AUTOSAR XML (schema 4-0-3)
package /ComponentTypes
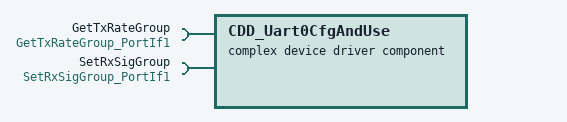
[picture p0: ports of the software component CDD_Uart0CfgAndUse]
  complex device driver sw component type CDD_Uart0CfgAndUse
    require port GetTxRateGroup: client-com-spec=Oper, required-interface=GetTxRateGroup_PortIf1
    require port SetRxSigGroup: client-com-spec=Oper, required-interface=SetRxSigGroup_PortIf1
    behavior CDD_Uart0CfgAndUse_InternalBehavior
      exclusive area ExclsvAr1Uart0DrvrTxRxBuf
      ar-typed-per-instance-memorys:
        13 x data, all with sw-calibration-access=READ-ONLY:
          PrevDmaTrfCnt: type=uint16
          Uart0100MilliSecBufCnt: type=Ary1D_u8_2048_Uart0CfgAndUse
          Uart0100MilliSecReadCmpl: type=uint8
          Uart010MilliSecBufCnt: type=Ary1D_u8_2048_Uart0CfgAndUse
          Uart010MilliSecReadCmpl: type=uint8
          Uart02MilliSecBufCnt: type=Ary1D_u8_2048_Uart0CfgAndUse
          Uart0DiagcFrmErrCntr: type=uint32
          Uart0DiagcOvrrunErrCntr: type=uint32
          Uart0DiagcParErrCntr: type=uint32
          Uart0DiagcRxMaxDataErrCntr: type=uint32
          Uart0NrOfPnd100MilliSecFrmCnt: type=uint8
          Uart0NrOfPnd10MilliSecFrmCnt: type=uint8
          Uart0RxPrevLoopDataUnread: type=uint8
      5 x timing event:
        CDD_Uart0CfgAndUse_InitEvent: start-on-event=Uart0CfgAndUseInit1, period=0
        TMT_Uart0CfgAndUsePer1: start-on-event=Uart0CfgAndUsePer1, period=0.002
        TMT_Uart0CfgAndUsePer2: start-on-event=Uart0CfgAndUsePer2, period=0.002
        TMT_Uart0CfgAndUsePer3: start-on-event=Uart0CfgAndUsePer3, period=0.01
        TMT_Uart0CfgAndUsePer4: start-on-event=Uart0CfgAndUsePer4, period=0.1
      5 x runnable:
        Uart0CfgAndUseInit1
        Uart0CfgAndUsePer1
          sync call SC_SetRxSigGroup_Oper: operation=SetRxSigGroup.Oper, timeout=0
        Uart0CfgAndUsePer2: can-enter-exclusive-area=ExclsvAr1Uart0DrvrTxRxBuf
          sync call SC_GetTxRateGroup_Oper: operation=GetTxRateGroup.Oper, timeout=0
        Uart0CfgAndUsePer3
          sync call SC_GetTxRateGroup_Oper: operation=GetTxRateGroup.Oper, timeout=0
        Uart0CfgAndUsePer4
          sync call SC_GetTxRateGroup_Oper: operation=GetTxRateGroup.Oper, timeout=0
  swc implementation CDD_Uart0CfgAndUse_Implementation: behavior=CDD_Uart0CfgAndUse_InternalBehavior
    code-descriptors:
      code Default: artifact-descriptors=autosar-engineering-object={short-label=Default, category=SWSRC}
